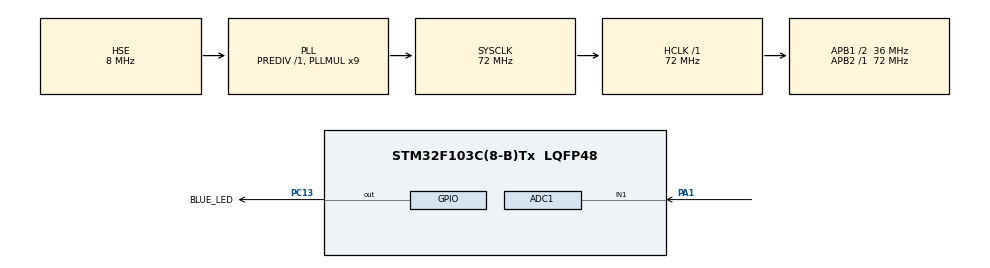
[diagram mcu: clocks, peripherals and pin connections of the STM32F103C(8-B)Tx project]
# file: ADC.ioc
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Mcu.Family=STM32F1
RCC.PLLSourceVirtual=RCC_PLLSOURCE_HSE
NVIC.ADC1_2_IRQn=true\:0\:0\:false\:false\:true\:true\:true
ADC1.Rank-0\#ChannelRegularConversion=1
PD1-OSC_OUT.Mode=HSE-External-Oscillator
ADC1.ContinuousConvMode=DISABLE
PC13-TAMPER-RTC.Signal=GPIO_Output
NVIC.TIM1_UP_IRQn=true\:0\:0\:false\:false\:true\:false\:true
PD0-OSC_IN.Signal=RCC_OSC_IN
RCC.APB1CLKDivider=RCC_HCLK_DIV2
RCC.SYSCLKSource=RCC_SYSCLKSOURCE_PLLCLK
ProjectManager.StackSize=0x400
PD1-OSC_OUT.Signal=RCC_OSC_OUT
RCC.ADCPresc=RCC_ADCPCLK2_DIV6
PA13.Signal=SYS_JTMS-SWDIO
ProjectManager.TargetToolchain=STM32CubeIDE
RCC.HCLKFreq_Value=72000000
RCC.APB2TimFreq_Value=72000000
RCC.USBFreq_Value=72000000
PA1.Signal=ADCx_IN1
RCC.AHBFreq_Value=72000000
PD0-OSC_IN.Mode=HSE-External-Oscillator
ADC1.Channel-0\#ChannelRegularConversion=ADC_CHANNEL_1
board=custom
RCC.PLLMUL=RCC_PLL_MUL9
PC13-TAMPER-RTC.GPIO_Label=BLUE_LED
RCC.APB2Freq_Value=72000000
PA14.Mode=Serial_Wire
VP_SYS_VS_tim1.Mode=TIM1
ADC1.NbrOfConversion=1
PA13.Mode=Serial_Wire
Mcu.Name=STM32F103C(8-B)Tx
ADC1.SamplingTime-0\#ChannelRegularConversion=ADC_SAMPLETIME_28CYCLES_5
RCC.SYSCLKFreq_VALUE=72000000
Mcu.Package=LQFP48
ADC1.master=1
NVIC.TimeBase=TIM1_UP_IRQn
NVIC.TimeBaseIP=TIM1
PA14.Signal=SYS_JTCK-SWCLK
ProjectManager.HeapSize=0x200
NVIC.PriorityGroup=NVIC_PRIORITYGROUP_4
ADC1.NbrOfConversionFlag=1
SH.ADCx_IN1.0=ADC1_IN1,IN1
RCC.APB1TimFreq_Value=72000000
RCC.APB1Freq_Value=36000000

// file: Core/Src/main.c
/* USER CODE BEGIN Header */
/**
  ******************************************************************************
  * @file           : main.c
  * @brief          : Main program body
  ******************************************************************************
  * @attention
  *
  * <h2><center>&copy; Copyright (c) 2021 STMicroelectronics.
  * All rights reserved.</center></h2>
  *
  * This software component is licensed by ST under BSD 3-Clause license,
  * the "License"; You may not use this file except in compliance with the
  * License. You may obtain a copy of the License at:
  *                        opensource.org/licenses/BSD-3-Clause
  *
  ******************************************************************************
  */
/* USER CODE END Header */
#include "main.h"

ADC_HandleTypeDef hadc1;

/* USER CODE BEGIN PV */
uint16_t adc_value;
/* USER CODE END PV */

void SystemClock_Config(void);
static void MX_GPIO_Init(void);
static void MX_ADC1_Init(void);
/* USER CODE BEGIN PFP */
/*
__weak void HAL_ADC_ConvCpltCallback(ADC_HandleTypeDef* hadc){
	adc_value=HAL_ADC_GetValue(hadc);
	HAL_GPIO_TogglePin(BLUE_LED_GPIO_Port,BLUE_LED_Pin);
	HAL_ADC_Start_IT(hadc);
	HAL_Delay(50);
}*/

/* USER CODE END PFP */

int main(void)
{

  /* MCU Configuration--------------------------------------------------------*/

  /* Reset of all peripherals, Initializes the Flash interface and the Systick. */
  HAL_Init();

  /* Configure the system clock */
  SystemClock_Config();

  /* Initialize all configured peripherals */
  MX_GPIO_Init();
  MX_ADC1_Init();
  /* USER CODE BEGIN 2 */
  //HAL_ADC_Start_IT(&hadc1);
  /* USER CODE END 2 */

  /* Infinite loop */
  while (1)
  {
	  HAL_ADC_Start(&hadc1);
	  HAL_ADC_PollForConversion(&hadc1, 1000);
	  adc_value=HAL_ADC_GetValue(&hadc1);
	  if(adc_value>700){
		  HAL_GPIO_TogglePin(BLUE_LED_GPIO_Port,BLUE_LED_Pin);
		  HAL_Delay(50);
	  }
	  else{
		  HAL_GPIO_WritePin(BLUE_LED_GPIO_Port, BLUE_LED_Pin, GPIO_PIN_SET);
	  }
  }
}

void SystemClock_Config(void)
{
  RCC_OscInitTypeDef RCC_OscInitStruct = {0};
  RCC_ClkInitTypeDef RCC_ClkInitStruct = {0};
  RCC_PeriphCLKInitTypeDef PeriphClkInit = {0};

  /** Initializes the RCC Oscillators according to the specified parameters
  * in the RCC_OscInitTypeDef structure.
  */
  RCC_OscInitStruct.OscillatorType = RCC_OSCILLATORTYPE_HSE;
  RCC_OscInitStruct.HSEState = RCC_HSE_ON;
  RCC_OscInitStruct.HSEPredivValue = RCC_HSE_PREDIV_DIV1;
  RCC_OscInitStruct.HSIState = RCC_HSI_ON;
  RCC_OscInitStruct.PLL.PLLState = RCC_PLL_ON;
  RCC_OscInitStruct.PLL.PLLSource = RCC_PLLSOURCE_HSE;
  RCC_OscInitStruct.PLL.PLLMUL = RCC_PLL_MUL9;
  if (HAL_RCC_OscConfig(&RCC_OscInitStruct) != HAL_OK)
  {
    Error_Handler();
  }
  /** Initializes the CPU, AHB and APB buses clocks
  */
  RCC_ClkInitStruct.ClockType = RCC_CLOCKTYPE_HCLK|RCC_CLOCKTYPE_SYSCLK
                              |RCC_CLOCKTYPE_PCLK1|RCC_CLOCKTYPE_PCLK2;
  RCC_ClkInitStruct.SYSCLKSource = RCC_SYSCLKSOURCE_PLLCLK;
  RCC_ClkInitStruct.AHBCLKDivider = RCC_SYSCLK_DIV1;
  RCC_ClkInitStruct.APB1CLKDivider = RCC_HCLK_DIV2;
  RCC_ClkInitStruct.APB2CLKDivider = RCC_HCLK_DIV1;

  if (HAL_RCC_ClockConfig(&RCC_ClkInitStruct, FLASH_LATENCY_2) != HAL_OK)
  {
    Error_Handler();
  }
  PeriphClkInit.PeriphClockSelection = RCC_PERIPHCLK_ADC;
  PeriphClkInit.AdcClockSelection = RCC_ADCPCLK2_DIV6;
  if (HAL_RCCEx_PeriphCLKConfig(&PeriphClkInit) != HAL_OK)
  {
    Error_Handler();
  }
}

static void MX_ADC1_Init(void)
{

  ADC_ChannelConfTypeDef sConfig = {0};

  /** Common config
  */
  hadc1.Instance = ADC1;
  hadc1.Init.ScanConvMode = ADC_SCAN_DISABLE;
  hadc1.Init.ContinuousConvMode = DISABLE;
  hadc1.Init.DiscontinuousConvMode = DISABLE;
  hadc1.Init.ExternalTrigConv = ADC_SOFTWARE_START;
  hadc1.Init.DataAlign = ADC_DATAALIGN_RIGHT;
  hadc1.Init.NbrOfConversion = 1;
  if (HAL_ADC_Init(&hadc1) != HAL_OK)
  {
    Error_Handler();
  }
  /** Configure Regular Channel
  */
  sConfig.Channel = ADC_CHANNEL_1;
  sConfig.Rank = ADC_REGULAR_RANK_1;
  sConfig.SamplingTime = ADC_SAMPLETIME_28CYCLES_5;
  if (HAL_ADC_ConfigChannel(&hadc1, &sConfig) != HAL_OK)
  {
    Error_Handler();
  }

}

static void MX_GPIO_Init(void)
{
  GPIO_InitTypeDef GPIO_InitStruct = {0};

  /* GPIO Ports Clock Enable */
  __HAL_RCC_GPIOC_CLK_ENABLE();
  __HAL_RCC_GPIOD_CLK_ENABLE();
  __HAL_RCC_GPIOA_CLK_ENABLE();

  /*Configure GPIO pin Output Level */
  HAL_GPIO_WritePin(BLUE_LED_GPIO_Port, BLUE_LED_Pin, GPIO_PIN_RESET);

  /*Configure GPIO pin : BLUE_LED_Pin */
  GPIO_InitStruct.Pin = BLUE_LED_Pin;
  GPIO_InitStruct.Mode = GPIO_MODE_OUTPUT_PP;
  GPIO_InitStruct.Pull = GPIO_NOPULL;
  GPIO_InitStruct.Speed = GPIO_SPEED_FREQ_LOW;
  HAL_GPIO_Init(BLUE_LED_GPIO_Port, &GPIO_InitStruct);

}

 /**
  * @brief  Period elapsed callback in non blocking mode
  * @note   This function is called  when TIM1 interrupt took place, inside
  * HAL_TIM_IRQHandler(). It makes a direct call to HAL_IncTick() to increment
  * a global variable "uwTick" used as application time base.
  * @param  htim : TIM handle
  * @retval None
  */
void HAL_TIM_PeriodElapsedCallback(TIM_HandleTypeDef *htim)
{
  if (htim->Instance == TIM1) {
    HAL_IncTick();
  }
}

void Error_Handler(void)
{
  __disable_irq();
  while (1)
  {
  }
}

/************************ (C) COPYRIGHT STMicroelectronics *****END OF FILE****/
